VERSION ""

NS_ :

BS_:

BU_: EPS ESP_ECU VCU BCM MCU ADAS_ECU MPC_CAM BSD XXX

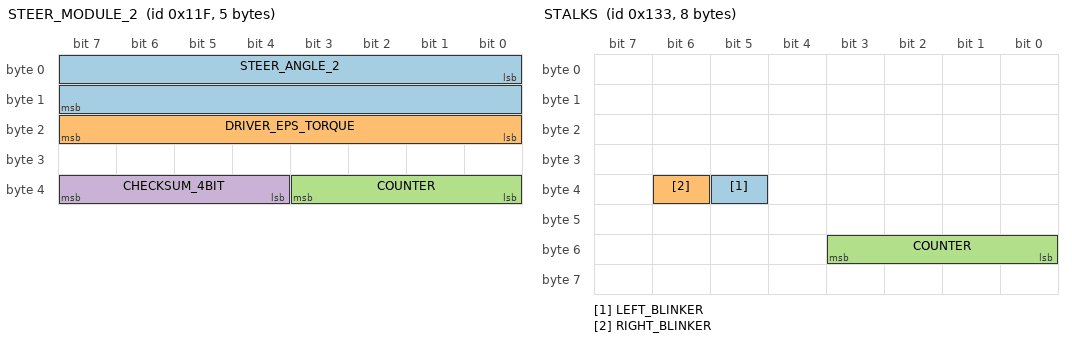
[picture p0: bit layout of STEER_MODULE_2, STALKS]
BO_ 287 STEER_MODULE_2: 5 EPS
 SG_ STEER_ANGLE_2 : 0|16@1- (0.1,0) [-780|780] "deg" MCU,ADAS_ECU
 SG_ DRIVER_EPS_TORQUE : 16|8@1+ (1,0) [0|255] "" MCU,ADAS_ECU
 SG_ COUNTER : 35|4@0+ (1,0) [0|15] "" MCU
 SG_ CHECKSUM_4BIT : 39|4@0+ (1,0) [0|15] "" MCU

BO_ 307 STALKS: 8 BCM
 SG_ LEFT_BLINKER : 37|1@0+ (1,0) [0|1] "" MCU
 SG_ RIGHT_BLINKER : 38|1@0+ (1,0) [0|1] "" MCU
 SG_ COUNTER : 48|4@1+ (1,0) [0|15] "" MCU

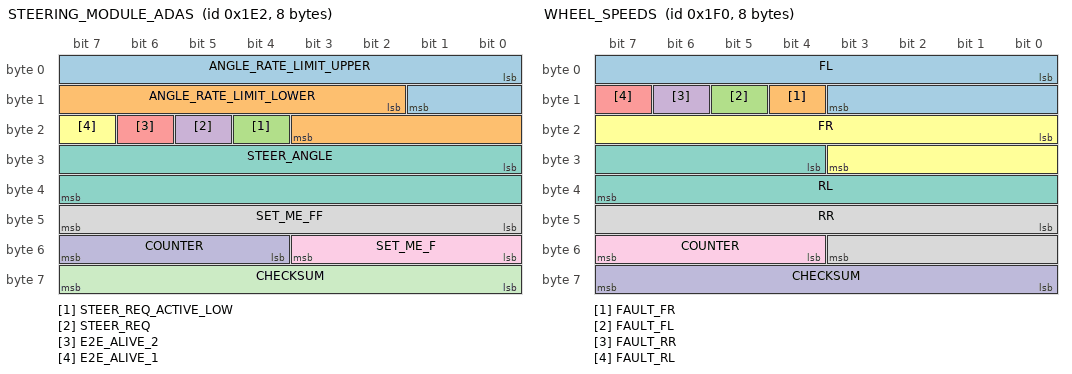
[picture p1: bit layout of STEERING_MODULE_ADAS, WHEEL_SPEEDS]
BO_ 482 STEERING_MODULE_ADAS: 8 ADAS_ECU
 SG_ ANGLE_RATE_LIMIT_UPPER : 0|10@1- (1,0) [-512|511] "" EPS
 SG_ ANGLE_RATE_LIMIT_LOWER : 10|10@1- (1,0) [-512|511] "" EPS
 SG_ STEER_REQ_ACTIVE_LOW : 20|1@0+ (1,0) [0|1] "" EPS
 SG_ STEER_REQ : 21|1@0+ (1,0) [0|1] "" EPS
 SG_ E2E_ALIVE_2 : 22|1@0+ (1,0) [0|1] "" EPS
 SG_ E2E_ALIVE_1 : 23|1@0+ (1,0) [0|1] "" EPS
 SG_ STEER_ANGLE : 24|16@1- (0.1,0) [-3276.8|3276.7] "deg" EPS
 SG_ SET_ME_FF : 47|8@0+ (1,0) [0|255] "" EPS
 SG_ SET_ME_F : 48|4@1+ (1,0) [0|15] "" EPS
 SG_ COUNTER : 55|4@0+ (1,0) [0|15] "" EPS
 SG_ CHECKSUM : 56|8@1+ (1,0) [0|255] "" EPS

BO_ 496 WHEEL_SPEEDS: 8 ESP_ECU
 SG_ FL : 0|12@1+ (0.0725,0) [0|296.9] "kph" MCU
 SG_ FAULT_FR : 12|1@1+ (1,0) [0|1] "" MCU
 SG_ FAULT_FL : 13|1@1+ (1,0) [0|1] "" MCU
 SG_ FAULT_RR : 14|1@1+ (1,0) [0|1] "" MCU
 SG_ FAULT_RL : 15|1@1+ (1,0) [0|1] "" MCU
 SG_ FR : 16|12@1+ (0.0725,0) [0|296.9] "kph" MCU
 SG_ RL : 28|12@1+ (0.0725,0) [0|296.9] "kph" MCU
 SG_ RR : 40|12@1+ (0.0725,0) [0|296.9] "kph" MCU
 SG_ COUNTER : 55|4@0+ (1,0) [0|15] "" MCU
 SG_ CHECKSUM : 56|8@1+ (1,0) [0|255] "" MCU

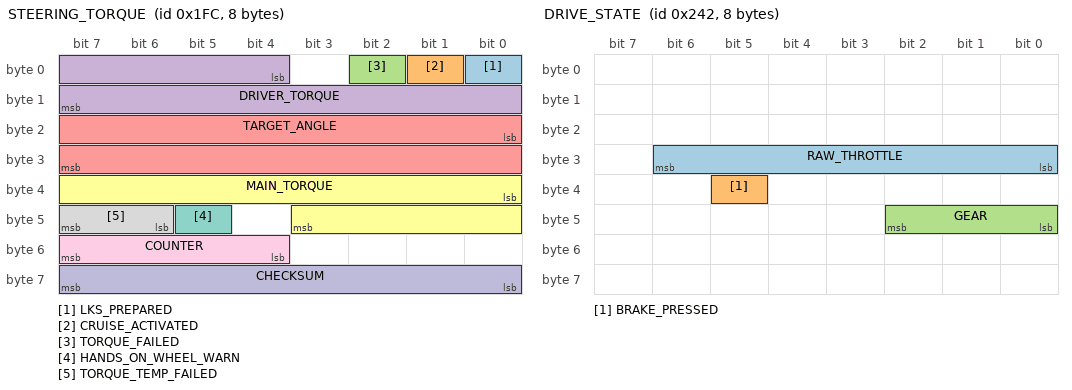
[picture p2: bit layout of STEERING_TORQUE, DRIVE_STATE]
BO_ 508 STEERING_TORQUE: 8 EPS
 SG_ LKS_PREPARED : 0|1@1+ (1,0) [0|1] "" MCU,ADAS_ECU
 SG_ CRUISE_ACTIVATED : 1|1@1+ (1,0) [0|1] "" MCU,ADAS_ECU
 SG_ TORQUE_FAILED : 2|1@1+ (1,0) [0|1] "" MCU,ADAS_ECU
 SG_ DRIVER_TORQUE : 4|12@1- (0.1,0) [-204.8|204.7] "Nm" MCU,ADAS_ECU
 SG_ TARGET_ANGLE : 16|16@1- (0.1,0) [-3276.8|3276.7] "deg" MCU,ADAS_ECU
 SG_ MAIN_TORQUE : 32|12@1- (1,0) [-2048|2047] "" MCU,ADAS_ECU
 SG_ HANDS_ON_WHEEL_WARN : 45|1@1+ (1,0) [0|1] "" MCU,ADAS_ECU
 SG_ TORQUE_TEMP_FAILED : 46|2@1+ (1,0) [0|3] "" MCU,ADAS_ECU
 SG_ COUNTER : 52|4@1+ (1,0) [0|15] "" MCU
 SG_ CHECKSUM : 56|8@1+ (1,0) [0|255] "" MCU

BO_ 537 SL7_BRAKE: 8 ESP_ECU
 SG_ BRAKE_PRESSED : 2|1@0+ (1,0) [0|1] "" XXX

BO_ 578 DRIVE_STATE: 8 VCU
 SG_ RAW_THROTTLE : 30|7@0+ (1,0) [0|127] "" MCU
 SG_ BRAKE_PRESSED : 37|1@0+ (1,0) [0|1] "" MCU,ADAS_ECU
 SG_ GEAR : 40|3@1+ (1,0) [0|7] "" MCU

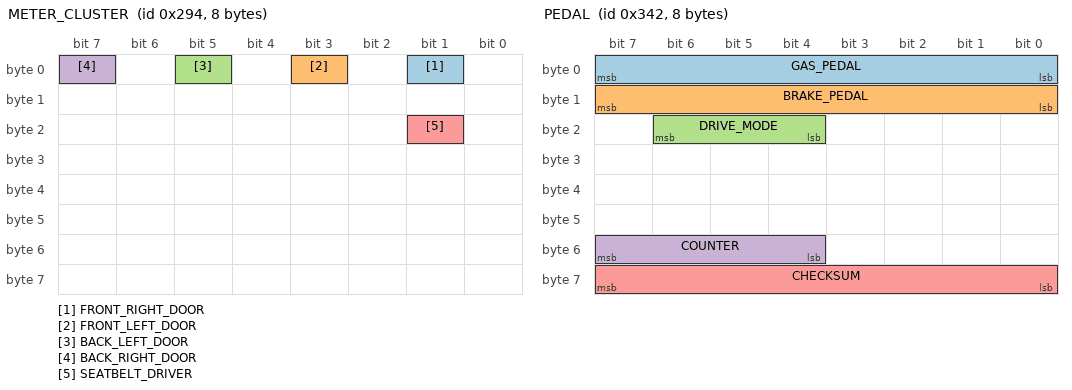
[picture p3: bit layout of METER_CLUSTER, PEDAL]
BO_ 660 METER_CLUSTER: 8 BCM
 SG_ FRONT_RIGHT_DOOR : 1|1@1+ (1,0) [0|1] "" MCU
 SG_ FRONT_LEFT_DOOR : 3|1@0+ (1,0) [0|1] "" MCU
 SG_ BACK_LEFT_DOOR : 5|1@1+ (1,0) [0|1] "" MCU
 SG_ BACK_RIGHT_DOOR : 7|1@0+ (1,0) [0|1] "" MCU
 SG_ SEATBELT_DRIVER : 17|1@0+ (1,0) [0|1] "" MCU

BO_ 790 LKAS_HUD_ADAS: 8 MPC_CAM
 SG_ HMA_STATE : 3|4@0+ (1,0) [0|15] "" MCU
 SG_ LEFT_LANE_STATE : 4|2@1+ (1,0) [0|3] "" MCU
 SG_ LKS_MODE : 6|2@1+ (1,0) [0|3] "" MCU
 SG_ HANDS_ON_WHEEL_REQ : 10|1@1+ (1,0) [0|1] "" MCU
 SG_ TJA_ICA_STATE : 11|4@1+ (1,0) [0|15] "" MCU
 SG_ HMA_ON_OFF : 15|1@0+ (1,0) [0|1] "" MCU
 SG_ LKAS_OUTPUT : 16|11@1- (1,0) [-1024|1023] "" MCU
 SG_ LKAS_REQ_PREPARE : 27|1@1+ (1,0) [0|1] "" MCU
 SG_ LKAS_ACTIVE : 28|1@1+ (1,0) [0|1] "" MCU
 SG_ SLA_STATE : 29|3@1+ (1,0) [0|7] "" MCU
 SG_ SET_ME_3 : 32|2@1+ (1,0) [0|3] "" MCU
 SG_ RIGHT_LANE_STATE : 34|2@1+ (1,0) [0|3] "" MCU
 SG_ LKAS_STATE : 36|4@1+ (1,0) [0|15] "" MCU
 SG_ SPEED_LIMIT_VALUE : 40|8@1+ (5,-5) [-5|1270] "kph" MCU
 SG_ LDSW_TYPE : 49|2@0+ (1,0) [0|3] "" MCU
 SG_ COUNTER : 52|4@1+ (1,0) [0|15] "" MCU
 SG_ CHECKSUM : 56|8@1+ (1,0) [0|255] "" MCU

BO_ 813 ACC_HUD_ADAS: 8 ADAS_ECU
 SG_ SET_SPEED : 0|9@1+ (0.5,0) [0|255.5] "kph" MCU
 SG_ HAS_LEAD : 9|1@1+ (1,0) [0|1] "" MCU
 SG_ SET_DISTANCE : 12|3@0+ (1,0) [0|7] "" MCU
 SG_ AEB : 16|1@1+ (1,0) [0|1] "" MCU
 SG_ FCW : 17|1@1+ (1,0) [0|1] "" MCU
 SG_ CRUISE_STATE : 44|4@1+ (1,0) [0|15] "" MCU
 SG_ ACC_ON2 : 20|1@0+ (1,0) [0|1] "" MCU
 SG_ ACC_ON1 : 22|1@0+ (1,0) [0|1] "" MCU
 SG_ SET_ME_XFF : 47|8@0+ (1,0) [0|255] "" MCU
 SG_ COUNTER : 48|4@1+ (1,0) [0|15] "" MCU
 SG_ SET_ME_XF : 55|4@0+ (1,0) [0|15] "" MCU
 SG_ CHECKSUM : 56|8@1+ (1,0) [0|255] "" MCU

BO_ 814 ACC_CMD: 8 ADAS_ECU
 SG_ ACCEL_CMD : 0|8@1+ (0.05,-5) [-5|7.75] "m/s^2" MCU
 SG_ ACC_ON_1 : 9|1@0+ (1,0) [0|1] "" MCU
 SG_ SET_ME_25_1 : 10|6@1+ (1,0) [0|63] "" MCU
 SG_ ACC_ON_2 : 17|1@0+ (1,0) [0|1] "" MCU
 SG_ SET_ME_25_2 : 18|6@1+ (1,0) [0|63] "" MCU
 SG_ DECEL_FACTOR : 24|4@1+ (1,0) [0|15] "" MCU
 SG_ SET_ME_X8 : 31|4@0+ (1,0) [0|15] "" MCU
 SG_ ACCEL_FACTOR : 32|4@1+ (1,0) [0|15] "" MCU
 SG_ CMD_REQ_ACTIVE_LOW : 36|1@0+ (1,0) [0|1] "" MCU
 SG_ SET_ME_1 : 38|1@0+ (1,0) [0|1] "" MCU
 SG_ STANDSTILL_RESUME : 39|1@0+ (1,0) [0|1] "" MCU
 SG_ STANDSTILL_STATE : 40|1@0+ (1,0) [0|1] "" MCU
 SG_ ACC_REQ_NOT_STANDSTILL : 43|1@0+ (1,0) [0|1] "" MCU
 SG_ ACC_CONTROLLABLE_AND_ON : 44|1@0+ (1,0) [0|1] "" MCU
 SG_ ACC_OVERRIDE_OR_STANDSTILL : 45|1@0+ (1,0) [0|1] "" MCU
 SG_ COUNTER : 48|4@1+ (1,0) [0|15] "" MCU
 SG_ SET_ME_XF : 55|4@0+ (1,0) [0|15] "" MCU
 SG_ CHECKSUM : 56|8@1+ (1,0) [0|255] "" MCU

BO_ 834 PEDAL: 8 VCU
 SG_ GAS_PEDAL : 0|8@1+ (0.01,0) [0|2.55] "" MCU
 SG_ BRAKE_PEDAL : 8|8@1+ (0.01,0) [0|2.55] "" MCU
 SG_ DRIVE_MODE : 22|3@0+ (1,0) [0|7] "" XXX
 SG_ COUNTER : 55|4@0+ (1,0) [0|15] "" MCU
 SG_ CHECKSUM : 56|8@1+ (1,0) [0|255] "" MCU

BO_ 860 GEAR_STATE: 8 VCU
 SG_ GEAR_STATE : 8|3@1+ (1,0) [0|7] "" XXX

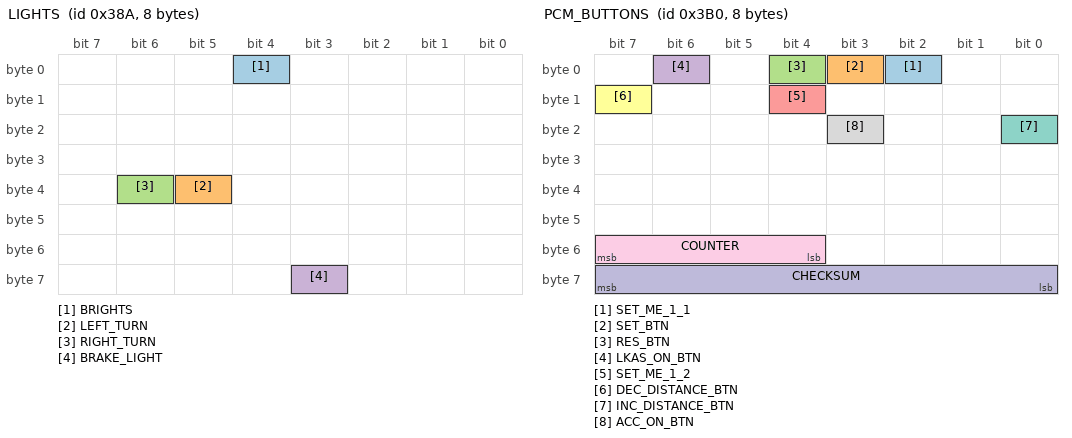
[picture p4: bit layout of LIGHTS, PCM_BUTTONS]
BO_ 906 LIGHTS: 8 BCM
 SG_ BRIGHTS : 4|1@0+ (1,0) [0|1] "" XXX
 SG_ LEFT_TURN : 37|1@0+ (1,0) [0|1] "" XXX
 SG_ RIGHT_TURN : 38|1@0+ (1,0) [0|1] "" XXX
 SG_ BRAKE_LIGHT : 59|1@0+ (1,0) [0|1] "" XXX

BO_ 944 PCM_BUTTONS: 8 MCU
 SG_ SET_ME_1_1 : 2|1@0+ (1,0) [0|1] "" MCU
 SG_ SET_BTN : 3|1@0+ (1,0) [0|1] "" MCU
 SG_ RES_BTN : 4|1@0+ (1,0) [0|1] "" MCU
 SG_ LKAS_ON_BTN : 6|1@0+ (1,0) [0|1] "" MCU
 SG_ SET_ME_1_2 : 12|1@0+ (1,0) [0|1] "" MCU
 SG_ DEC_DISTANCE_BTN : 15|1@0+ (1,0) [0|1] "" MCU
 SG_ INC_DISTANCE_BTN : 16|1@0+ (1,0) [0|1] "" MCU
 SG_ ACC_ON_BTN : 19|1@0+ (1,0) [0|1] "" MCU
 SG_ COUNTER : 55|4@0+ (1,0) [0|15] "" MCU
 SG_ CHECKSUM : 63|8@0+ (1,0) [0|255] "" MCU

BO_ 1028 IGNITION: 8 BCM
 SG_ IGNITION_ON : 6|1@0+ (1,0) [0|1] "" XXX

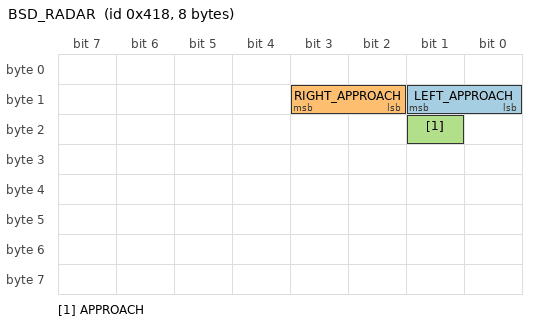
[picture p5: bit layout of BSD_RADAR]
BO_ 1048 BSD_RADAR: 8 BSD
 SG_ LEFT_APPROACH : 9|2@0+ (1,0) [0|3] "" MCU,ADAS_ECU
 SG_ RIGHT_APPROACH : 11|2@0+ (1,0) [0|3] "" MCU,ADAS_ECU
 SG_ APPROACH : 17|1@0+ (1,0) [0|1] "" MCU,ADAS_ECU

CM_ "BYD Sealion 7 (e-Platform 3.0) chassis CAN, 500 kbit/s.
Sources: opendbc PR #3352 (Sealion 7) for the message set, PR #3337 (Atto 3) and HotIce0's
vendor-firmware DBC for signal layouts. Checksum on every 8-byte frame:
data[7] = (~sum(data[0:7])) & 0xFF.";

CM_ BO_ 287 "DRIVER_EPS_TORQUE is named per PR #3337/#3352; BYD's own firmware decodes the same
bits as a steering rate. Use STEERING_TORQUE.DRIVER_TORQUE for driver override.";

CM_ SG_ 496 FL "Scale provisional - calibrate against GPS in bring-up B5.";

CM_ BO_ 508 "Full layout, agreed by PR #3337 and HotIce0's vendor DBC. PR #3352 inherited
bukapilot's stub (MAIN_TORQUE 0|16) which packs the EPS status bits into a fake torque value.
EPS state nibble = 8 + LKS_PREPARED + 2*CRUISE_ACTIVATED: 8 off, 9 prepared, 10 actuating,
11 latched dropout. On the pre-2021 platform this lived on 0x318, which reads constant 0xFF
here - never read state from it.";

CM_ BO_ 813 "SET_SPEED is 9 bits per HotIce0; bit 8 is unallocated in the 8-bit reading, so this
is a safe superset.
CRUISE_STATE (44|4) is the real cruise state, NOT PR #3337/#3352's ACC_STATE at 19|3 - byte 2 is
a constant 0x3c on this car, so that field can only ever read 7 (ERROR) and engagement is
impossible. Measured over a 47 kph drive: 0=off, 1=available (ACC_CMD ACC_CONTROLLABLE_AND_ON
clear), 2=engaged (ON bit set, 100%), 3=engaged and commanding accel (mean +1.14 m/s^2).";

CM_ BO_ 814 "ACCEL_CMD in physical m/s^2, numerically identical to PR #3352's (1,-100) raw form.
The SET_ME_25_*/ACCEL_FACTOR/DECEL_FACTOR split is kept because it is the form with real-car TX
evidence; HotIce0 reads the same bytes as COMFORT_BAND_* and JERK_*_LIMIT. Confirm in B6.";

CM_ BO_ 944 "Button bits differ between BYD models - this is the Atto 3 table. Capture on the
Sealion 7 in bring-up B4.";

VAL_ 578 GEAR 1 "PARK" 2 "REVERSE" 3 "NEUTRAL" 4 "DRIVE" ;
VAL_ 813 CRUISE_STATE 0 "OFF" 1 "AVAILABLE" 2 "ENGAGED" 3 "ENGAGED_ACCELERATING" ;
VAL_ 790 LKAS_STATE 0 "OFF" 1 "PASSIVE" 2 "ACTIVE" 3 "ACTIVE" 4 "FAULT" ;
VAL_ 508 TORQUE_TEMP_FAILED 0 "OK" 1 "DERATE" 2 "DERATE" 3 "FAILED" ;

CM_ SG_ 790 SET_ME_3 "Bits 32-33. The camera sets these on every frame; they were undefined, so
the packer zeroed them and our regenerated 0x316 differed from stock. Passthrough only.";
